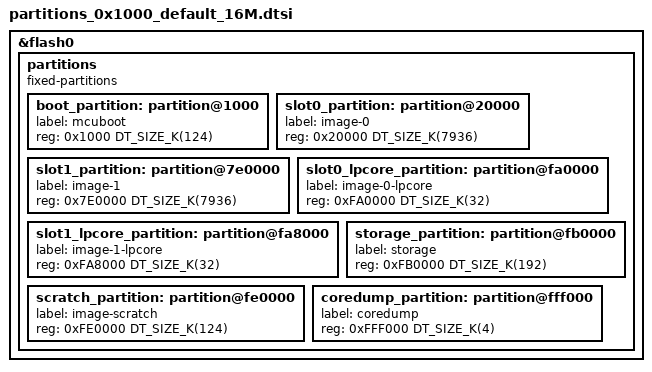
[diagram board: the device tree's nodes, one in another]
/*
 * Copyright (c) 2024-2025 Espressif Systems (Shanghai) Co., Ltd.
 *
 * SPDX-License-Identifier: Apache-2.0
 */

&flash0 {
	partitions {
		compatible = "fixed-partitions";
		#address-cells = <1>;
		#size-cells = <1>;

		boot_partition: partition@1000 {
			label = "mcuboot";
			reg = <0x1000 DT_SIZE_K(124)>;
		};

		slot0_partition: partition@20000 {
			label = "image-0";
			reg = <0x20000 DT_SIZE_K(7936)>;
		};

		slot1_partition: partition@7e0000 {
			label = "image-1";
			reg = <0x7E0000 DT_SIZE_K(7936)>;
		};

		slot0_lpcore_partition: partition@fa0000 {
			label = "image-0-lpcore";
			reg = <0xFA0000 DT_SIZE_K(32)>;
		};

		slot1_lpcore_partition: partition@fa8000 {
			label = "image-1-lpcore";
			reg = <0xFA8000 DT_SIZE_K(32)>;
		};

		storage_partition: partition@fb0000 {
			label = "storage";
			reg = <0xFB0000 DT_SIZE_K(192)>;
		};

		scratch_partition: partition@fe0000 {
			label = "image-scratch";
			reg = <0xFE0000 DT_SIZE_K(124)>;
		};

		coredump_partition: partition@fff000 {
			label = "coredump";
			reg = <0xFFF000 DT_SIZE_K(4)>;
		};
	};
};

/* Remaining flash size is 0kB
 * Last used address is 0xFFFFFF
 */
